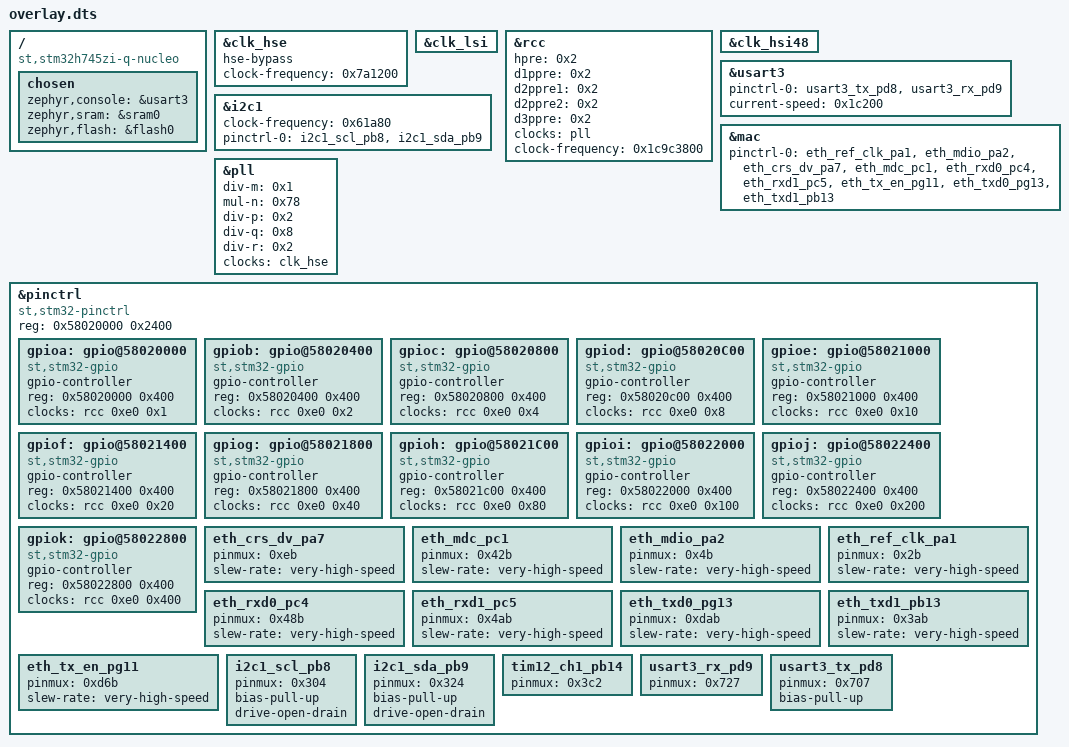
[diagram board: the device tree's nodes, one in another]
/ {
	compatible = "st,stm32h745zi-q-nucleo";
	chosen {
		zephyr,console = &usart3;
		zephyr,sram = &sram0;
		zephyr,flash = &flash0;
	};
};
&clk_hse{
	status = "okay";
	hse-bypass;
	clock-frequency = < 0x7a1200 >;
};
&clk_lsi{
	status = "okay";
};
&rcc{
	hpre = < 0x2 >;
	d1ppre = < 0x2 >;
	d2ppre1 = < 0x2 >;
	d2ppre2 = < 0x2 >;
	d3ppre = < 0x2 >;
	clocks = < &pll >;
	clock-frequency = < 0x1c9c3800 >;
};
&clk_hsi48{
	status = "okay";
};
&usart3{
	status = "okay";
	pinctrl-0 = < &usart3_tx_pd8 &usart3_rx_pd9 >;
	pinctrl-names = "default";
	current-speed = < 0x1c200 >;
};
&i2c1{
	clock-frequency = < 0x61a80 >;
	status = "okay";
	pinctrl-0 = < &i2c1_scl_pb8 &i2c1_sda_pb9 >;
	pinctrl-names = "default";
};
&mac{
	status = "okay";
	pinctrl-0 = < &eth_ref_clk_pa1 &eth_mdio_pa2 &eth_crs_dv_pa7 &eth_mdc_pc1 &eth_rxd0_pc4 &eth_rxd1_pc5 &eth_tx_en_pg11 &eth_txd0_pg13 &eth_txd1_pb13 >;
	pinctrl-names = "default";
};
&pll{
	status = "okay";
	div-m = < 0x1 >;
	mul-n = < 0x78 >;
	div-p = < 0x2 >;
	div-q = < 0x8 >;
	div-r = < 0x2 >;
	clocks = < &clk_hse >;
};
&pinctrl{
	compatible = "st,stm32-pinctrl";
	#address-cells = < 0x1 >;
	#size-cells = < 0x1 >;
	reg = < 0x58020000 0x2400 >;
	gpioa: gpio@58020000 {
		compatible = "st,stm32-gpio";
		gpio-controller;
		#gpio-cells = < 0x2 >;
		reg = < 0x58020000 0x400 >;
		clocks = < &rcc 0xe0 0x1 >;
	};
	gpiob: gpio@58020400 {
		compatible = "st,stm32-gpio";
		gpio-controller;
		#gpio-cells = < 0x2 >;
		reg = < 0x58020400 0x400 >;
		clocks = < &rcc 0xe0 0x2 >;
	};
	gpioc: gpio@58020800 {
		compatible = "st,stm32-gpio";
		gpio-controller;
		#gpio-cells = < 0x2 >;
		reg = < 0x58020800 0x400 >;
		clocks = < &rcc 0xe0 0x4 >;
	};
	gpiod: gpio@58020C00 {
		compatible = "st,stm32-gpio";
		gpio-controller;
		#gpio-cells = < 0x2 >;
		reg = < 0x58020c00 0x400 >;
		clocks = < &rcc 0xe0 0x8 >;
	};
	gpioe: gpio@58021000 {
		compatible = "st,stm32-gpio";
		gpio-controller;
		#gpio-cells = < 0x2 >;
		reg = < 0x58021000 0x400 >;
		clocks = < &rcc 0xe0 0x10 >;
	};
	gpiof: gpio@58021400 {
		compatible = "st,stm32-gpio";
		gpio-controller;
		#gpio-cells = < 0x2 >;
		reg = < 0x58021400 0x400 >;
		clocks = < &rcc 0xe0 0x20 >;
	};
	gpiog: gpio@58021800 {
		compatible = "st,stm32-gpio";
		gpio-controller;
		#gpio-cells = < 0x2 >;
		reg = < 0x58021800 0x400 >;
		clocks = < &rcc 0xe0 0x40 >;
	};
	gpioh: gpio@58021C00 {
		compatible = "st,stm32-gpio";
		gpio-controller;
		#gpio-cells = < 0x2 >;
		reg = < 0x58021c00 0x400 >;
		clocks = < &rcc 0xe0 0x80 >;
	};
	gpioi: gpio@58022000 {
		compatible = "st,stm32-gpio";
		gpio-controller;
		#gpio-cells = < 0x2 >;
		reg = < 0x58022000 0x400 >;
		clocks = < &rcc 0xe0 0x100 >;
	};
	gpioj: gpio@58022400 {
		compatible = "st,stm32-gpio";
		gpio-controller;
		#gpio-cells = < 0x2 >;
		reg = < 0x58022400 0x400 >;
		clocks = < &rcc 0xe0 0x200 >;
	};
	gpiok: gpio@58022800 {
		compatible = "st,stm32-gpio";
		gpio-controller;
		#gpio-cells = < 0x2 >;
		reg = < 0x58022800 0x400 >;
		clocks = < &rcc 0xe0 0x400 >;
	};
	eth_crs_dv_pa7: eth_crs_dv_pa7 {
		pinmux = < 0xeb >;
		slew-rate = "very-high-speed";
	};
	eth_mdc_pc1: eth_mdc_pc1 {
		pinmux = < 0x42b >;
		slew-rate = "very-high-speed";
	};
	eth_mdio_pa2: eth_mdio_pa2 {
		pinmux = < 0x4b >;
		slew-rate = "very-high-speed";
	};
	eth_ref_clk_pa1: eth_ref_clk_pa1 {
		pinmux = < 0x2b >;
		slew-rate = "very-high-speed";
	};
	eth_rxd0_pc4: eth_rxd0_pc4 {
		pinmux = < 0x48b >;
		slew-rate = "very-high-speed";
	};
	eth_rxd1_pc5: eth_rxd1_pc5 {
		pinmux = < 0x4ab >;
		slew-rate = "very-high-speed";
	};
	eth_txd0_pg13: eth_txd0_pg13 {
		pinmux = < 0xdab >;
		slew-rate = "very-high-speed";
	};
	eth_txd1_pb13: eth_txd1_pb13 {
		pinmux = < 0x3ab >;
		slew-rate = "very-high-speed";
	};
	eth_tx_en_pg11: eth_tx_en_pg11 {
		pinmux = < 0xd6b >;
		slew-rate = "very-high-speed";
	};
	i2c1_scl_pb8: i2c1_scl_pb8 {
		pinmux = < 0x304 >;
		bias-pull-up;
		drive-open-drain;
	};
	i2c1_sda_pb9: i2c1_sda_pb9 {
		pinmux = < 0x324 >;
		bias-pull-up;
		drive-open-drain;
	};
	tim12_ch1_pb14: tim12_ch1_pb14 {
		pinmux = < 0x3c2 >;
	};
	usart3_rx_pd9: usart3_rx_pd9 {
		pinmux = < 0x727 >;
	};
	usart3_tx_pd8: usart3_tx_pd8 {
		pinmux = < 0x707 >;
		bias-pull-up;
	};
};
